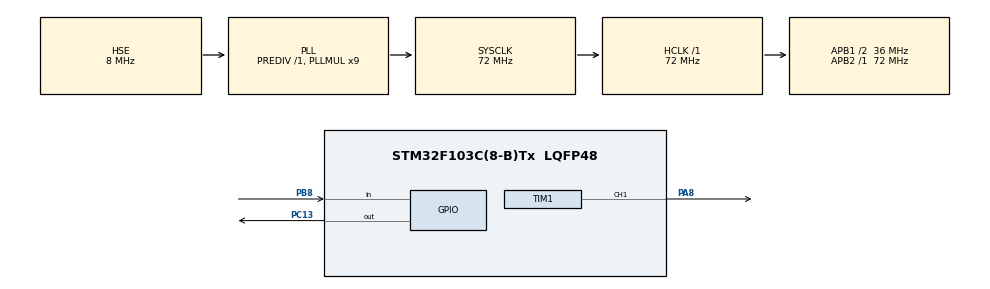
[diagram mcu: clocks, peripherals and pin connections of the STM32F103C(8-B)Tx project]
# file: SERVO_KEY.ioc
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Mcu.Family=STM32F1
Mcu.Name=STM32F103C(8-B)Tx
Mcu.Package=LQFP48
NVIC.PriorityGroup=NVIC_PRIORITYGROUP_4
PA13.Mode=Serial_Wire
PA13.Signal=SYS_JTMS-SWDIO
PA14.Mode=Serial_Wire
PA14.Signal=SYS_JTCK-SWCLK
PA8.Signal=S_TIM1_CH1
PB8.GPIO_PuPd=GPIO_PULLUP
PB8.Signal=GPIO_Input
PC13-TAMPER-RTC.Signal=GPIO_Output
PC14-OSC32_IN.Mode=LSE-External-Oscillator
PC14-OSC32_IN.Signal=RCC_OSC32_IN
PC15-OSC32_OUT.Mode=LSE-External-Oscillator
PC15-OSC32_OUT.Signal=RCC_OSC32_OUT
PD0-OSC_IN.Mode=HSE-External-Oscillator
PD0-OSC_IN.Signal=RCC_OSC_IN
PD1-OSC_OUT.Mode=HSE-External-Oscillator
PD1-OSC_OUT.Signal=RCC_OSC_OUT
ProjectManager.HeapSize=0x200
ProjectManager.StackSize=0x400
ProjectManager.TargetToolchain=MDK-ARM V5.32
RCC.AHBFreq_Value=72000000
RCC.APB1CLKDivider=RCC_HCLK_DIV2
RCC.APB1Freq_Value=36000000
RCC.APB1TimFreq_Value=72000000
RCC.APB2Freq_Value=72000000
RCC.APB2TimFreq_Value=72000000
RCC.HCLKFreq_Value=72000000
RCC.PLLMUL=RCC_PLL_MUL9
RCC.PLLSourceVirtual=RCC_PLLSOURCE_HSE
RCC.SYSCLKFreq_VALUE=72000000
RCC.SYSCLKSource=RCC_SYSCLKSOURCE_PLLCLK
RCC.USBFreq_Value=72000000
SH.S_TIM1_CH1.0=TIM1_CH1,PWM Generation1 CH1
TIM1.Channel-PWM\ Generation1\ CH1=TIM_CHANNEL_1
TIM1.Period=2000-1
TIM1.Prescaler=720-1
VP_TIM1_VS_ClockSourceINT.Mode=Internal
board=custom

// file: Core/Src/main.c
/* USER CODE BEGIN Header */
/**
  ******************************************************************************
  * @file           : main.c
  * @brief          : Main program body
  ******************************************************************************
  * @attention
  *
  * Copyright (c) 2025 STMicroelectronics.
  * All rights reserved.
  *
  * This software is licensed under terms that can be found in the LICENSE file
  * in the root directory of this software component.
  * If no LICENSE file comes with this software, it is provided AS-IS.
  *
  ******************************************************************************
  */
/* USER CODE END Header */
#include "main.h"

TIM_HandleTypeDef htim1;

void SystemClock_Config(void);
static void MX_GPIO_Init(void);
static void MX_TIM1_Init(void);

/* USER CODE BEGIN 0 */
//#define DEBOUNCE 20
//#define LONG 1000

typedef enum{
	STT_NULL = 0,
	STT_PRS,
	STT_LONG,
	STT_WAIT
} KeyState;

KeyState keystt = STT_NULL;

typedef enum{
	EVT_NULL = 0,
	EVT_CLK,
	EVT_LONG,
	EVT_DOUBLE
} KeyEvent;

KeyEvent keyevt = EVT_NULL;

typedef enum{
	SET_A,
	SET_B,
	SET_C
} ServoSet;

ServoSet srvset = SET_A;

//void Key_Click_Scan(void){
//
//	static uint32_t nowtime = 0;
//	nowtime = HAL_GetTick();//获取当前时间
//
//  uint16_t keyread = HAL_GPIO_ReadPin(GPIOB, GPIO_PIN_8);//识别输入口的状态
//
//	if(keystt == STT_NULL){
//		if(keyread == GPIO_PIN_RESET){
//			keystt = STT_PRS;
//		}
//	}
//
//
//
//	else if(keystt == STT_PRS){
//		if(nowtime - presstime >= DEBOUNCE){  // 按键按下
//			             // 消抖延时
//			keyread = HAL_GPIO_ReadPin(GPIOB, GPIO_PIN_8);
//			if(keyread == GPIO_PIN_RESET){
//				keystt = STT_LONG;
//				presstime = nowtime;//记录按下的时间
//
//			}
//			else{
//				keystt = STT_NULL;
//			}
//		}
//	}
//
//	else if(keystt == STT_LONG){
//		if(keyread == GPIO_PIN_SET){
//			if(nowtime - presstime < LONG){
//				HAL_GPIO_TogglePin(GPIOC, GPIO_PIN_13); // 翻转LED
//			}
//		}
//  }
//}
#define LONG 1000
#define DOUBLE 500

uint32_t nowtime = 0;
uint32_t presstime = 0;
uint32_t releasetime = 0;

void Key_Click_Scan(void){
	nowtime = HAL_GetTick();
  uint16_t keyread = HAL_GPIO_ReadPin(GPIOB, GPIO_PIN_8);

  if(keystt == STT_NULL){  // 按键按下
    if(keyread == GPIO_PIN_RESET){           // 第一次检测到按下
      HAL_Delay(20);              // 消抖延时
      keyread = HAL_GPIO_ReadPin(GPIOB, GPIO_PIN_8);
      if(keyread == GPIO_PIN_RESET){ // 确认按下
				presstime = nowtime;
        keystt = STT_PRS;          // 标记按键已处理
      }
    }
  }
  else if(keystt == STT_PRS){//按下后检测是否长按
		if(keyread == GPIO_PIN_SET){//释放时
			if(nowtime - presstime < LONG){//如果小于长按时长
			  keystt = STT_WAIT;
				releasetime = nowtime;

			}
			else{
			 keyevt = EVT_LONG;
       keystt = STT_NULL;
			}
		}
      // 按键释放，重置状态
  }
	else if(keystt == STT_WAIT){

		if(nowtime - releasetime < DOUBLE){
			if(keyread == GPIO_PIN_RESET){
				HAL_Delay(20);              // 消抖延时
				keyread = HAL_GPIO_ReadPin(GPIOB, GPIO_PIN_8);
				if(keyread == GPIO_PIN_RESET){ // 确认按下
					keystt = STT_NULL;
					keyevt = EVT_DOUBLE;
					HAL_Delay(50);
				}
			}
		}
		else{
			keystt = STT_NULL;
			keyevt = EVT_CLK;
		}
	}
}

void Key_Event(){
	if(keyevt!= EVT_NULL){
		if(keyevt == EVT_CLK){
			srvset = SET_A;
			HAL_GPIO_TogglePin(GPIOC, GPIO_PIN_13);
			keyevt = EVT_NULL;
		}
		else if (keyevt == EVT_LONG){
			HAL_GPIO_TogglePin(GPIOC, GPIO_PIN_13);
			srvset = SET_B;
			keyevt = EVT_NULL;
		}
		else if (keyevt ==EVT_DOUBLE){
			HAL_GPIO_TogglePin(GPIOC, GPIO_PIN_13);
			srvset = SET_C;
			keyevt = EVT_NULL;
		}
	}
}

/* USER CODE END 0 */

int main(void)
{

  /* MCU Configuration--------------------------------------------------------*/

  /* Reset of all peripherals, Initializes the Flash interface and the Systick. */
  HAL_Init();

  /* Configure the system clock */
  SystemClock_Config();

  /* Initialize all configured peripherals */
  MX_GPIO_Init();
  MX_TIM1_Init();
  /* USER CODE BEGIN 2 */
	HAL_TIM_PWM_Start(&htim1, TIM_CHANNEL_1);
  /* USER CODE END 2 */

  /* Infinite loop */
  /* USER CODE BEGIN WHILE */
  while (1)
  {
		uint16_t readkey = HAL_GPIO_ReadPin(GPIOC, GPIO_PIN_13);
		Key_Click_Scan();
		Key_Event();
		if(srvset == SET_A){
			__HAL_TIM_SET_COMPARE(&htim1, TIM_CHANNEL_1, 50);
		}
		else if(srvset == SET_B){
			__HAL_TIM_SET_COMPARE(&htim1, TIM_CHANNEL_1, 150);
		}
		else if(srvset == SET_C){
			__HAL_TIM_SET_COMPARE(&htim1, TIM_CHANNEL_1, 250);
		}
		HAL_Delay(20);
    /* USER CODE END WHILE */

  }
}

void SystemClock_Config(void)
{
  RCC_OscInitTypeDef RCC_OscInitStruct = {0};
  RCC_ClkInitTypeDef RCC_ClkInitStruct = {0};

  /** Initializes the RCC Oscillators according to the specified parameters
  * in the RCC_OscInitTypeDef structure.
  */
  RCC_OscInitStruct.OscillatorType = RCC_OSCILLATORTYPE_HSE;
  RCC_OscInitStruct.HSEState = RCC_HSE_ON;
  RCC_OscInitStruct.HSEPredivValue = RCC_HSE_PREDIV_DIV1;
  RCC_OscInitStruct.HSIState = RCC_HSI_ON;
  RCC_OscInitStruct.PLL.PLLState = RCC_PLL_ON;
  RCC_OscInitStruct.PLL.PLLSource = RCC_PLLSOURCE_HSE;
  RCC_OscInitStruct.PLL.PLLMUL = RCC_PLL_MUL9;
  if (HAL_RCC_OscConfig(&RCC_OscInitStruct) != HAL_OK)
  {
    Error_Handler();
  }

  /** Initializes the CPU, AHB and APB buses clocks
  */
  RCC_ClkInitStruct.ClockType = RCC_CLOCKTYPE_HCLK|RCC_CLOCKTYPE_SYSCLK
                              |RCC_CLOCKTYPE_PCLK1|RCC_CLOCKTYPE_PCLK2;
  RCC_ClkInitStruct.SYSCLKSource = RCC_SYSCLKSOURCE_PLLCLK;
  RCC_ClkInitStruct.AHBCLKDivider = RCC_SYSCLK_DIV1;
  RCC_ClkInitStruct.APB1CLKDivider = RCC_HCLK_DIV2;
  RCC_ClkInitStruct.APB2CLKDivider = RCC_HCLK_DIV1;

  if (HAL_RCC_ClockConfig(&RCC_ClkInitStruct, FLASH_LATENCY_2) != HAL_OK)
  {
    Error_Handler();
  }
}

static void MX_TIM1_Init(void)
{

  TIM_ClockConfigTypeDef sClockSourceConfig = {0};
  TIM_MasterConfigTypeDef sMasterConfig = {0};
  TIM_OC_InitTypeDef sConfigOC = {0};
  TIM_BreakDeadTimeConfigTypeDef sBreakDeadTimeConfig = {0};

  htim1.Instance = TIM1;
  htim1.Init.Prescaler = 720-1;
  htim1.Init.CounterMode = TIM_COUNTERMODE_UP;
  htim1.Init.Period = 2000-1;
  htim1.Init.ClockDivision = TIM_CLOCKDIVISION_DIV1;
  htim1.Init.RepetitionCounter = 0;
  htim1.Init.AutoReloadPreload = TIM_AUTORELOAD_PRELOAD_DISABLE;
  if (HAL_TIM_Base_Init(&htim1) != HAL_OK)
  {
    Error_Handler();
  }
  sClockSourceConfig.ClockSource = TIM_CLOCKSOURCE_INTERNAL;
  if (HAL_TIM_ConfigClockSource(&htim1, &sClockSourceConfig) != HAL_OK)
  {
    Error_Handler();
  }
  if (HAL_TIM_PWM_Init(&htim1) != HAL_OK)
  {
    Error_Handler();
  }
  sMasterConfig.MasterOutputTrigger = TIM_TRGO_RESET;
  sMasterConfig.MasterSlaveMode = TIM_MASTERSLAVEMODE_DISABLE;
  if (HAL_TIMEx_MasterConfigSynchronization(&htim1, &sMasterConfig) != HAL_OK)
  {
    Error_Handler();
  }
  sConfigOC.OCMode = TIM_OCMODE_PWM1;
  sConfigOC.Pulse = 0;
  sConfigOC.OCPolarity = TIM_OCPOLARITY_HIGH;
  sConfigOC.OCNPolarity = TIM_OCNPOLARITY_HIGH;
  sConfigOC.OCFastMode = TIM_OCFAST_DISABLE;
  sConfigOC.OCIdleState = TIM_OCIDLESTATE_RESET;
  sConfigOC.OCNIdleState = TIM_OCNIDLESTATE_RESET;
  if (HAL_TIM_PWM_ConfigChannel(&htim1, &sConfigOC, TIM_CHANNEL_1) != HAL_OK)
  {
    Error_Handler();
  }
  sBreakDeadTimeConfig.OffStateRunMode = TIM_OSSR_DISABLE;
  sBreakDeadTimeConfig.OffStateIDLEMode = TIM_OSSI_DISABLE;
  sBreakDeadTimeConfig.LockLevel = TIM_LOCKLEVEL_OFF;
  sBreakDeadTimeConfig.DeadTime = 0;
  sBreakDeadTimeConfig.BreakState = TIM_BREAK_DISABLE;
  sBreakDeadTimeConfig.BreakPolarity = TIM_BREAKPOLARITY_HIGH;
  sBreakDeadTimeConfig.AutomaticOutput = TIM_AUTOMATICOUTPUT_DISABLE;
  if (HAL_TIMEx_ConfigBreakDeadTime(&htim1, &sBreakDeadTimeConfig) != HAL_OK)
  {
    Error_Handler();
  }
  HAL_TIM_MspPostInit(&htim1);

}

static void MX_GPIO_Init(void)
{
  GPIO_InitTypeDef GPIO_InitStruct = {0};

  /* GPIO Ports Clock Enable */
  __HAL_RCC_GPIOC_CLK_ENABLE();
  __HAL_RCC_GPIOD_CLK_ENABLE();
  __HAL_RCC_GPIOA_CLK_ENABLE();
  __HAL_RCC_GPIOB_CLK_ENABLE();

  /*Configure GPIO pin Output Level */
  HAL_GPIO_WritePin(GPIOC, GPIO_PIN_13, GPIO_PIN_RESET);

  /*Configure GPIO pin : PC13 */
  GPIO_InitStruct.Pin = GPIO_PIN_13;
  GPIO_InitStruct.Mode = GPIO_MODE_OUTPUT_PP;
  GPIO_InitStruct.Pull = GPIO_NOPULL;
  GPIO_InitStruct.Speed = GPIO_SPEED_FREQ_LOW;
  HAL_GPIO_Init(GPIOC, &GPIO_InitStruct);

  /*Configure GPIO pin : PB8 */
  GPIO_InitStruct.Pin = GPIO_PIN_8;
  GPIO_InitStruct.Mode = GPIO_MODE_INPUT;
  GPIO_InitStruct.Pull = GPIO_PULLUP;
  HAL_GPIO_Init(GPIOB, &GPIO_InitStruct);

}

void Error_Handler(void)
{
  __disable_irq();
  while (1)
  {
  }
}
